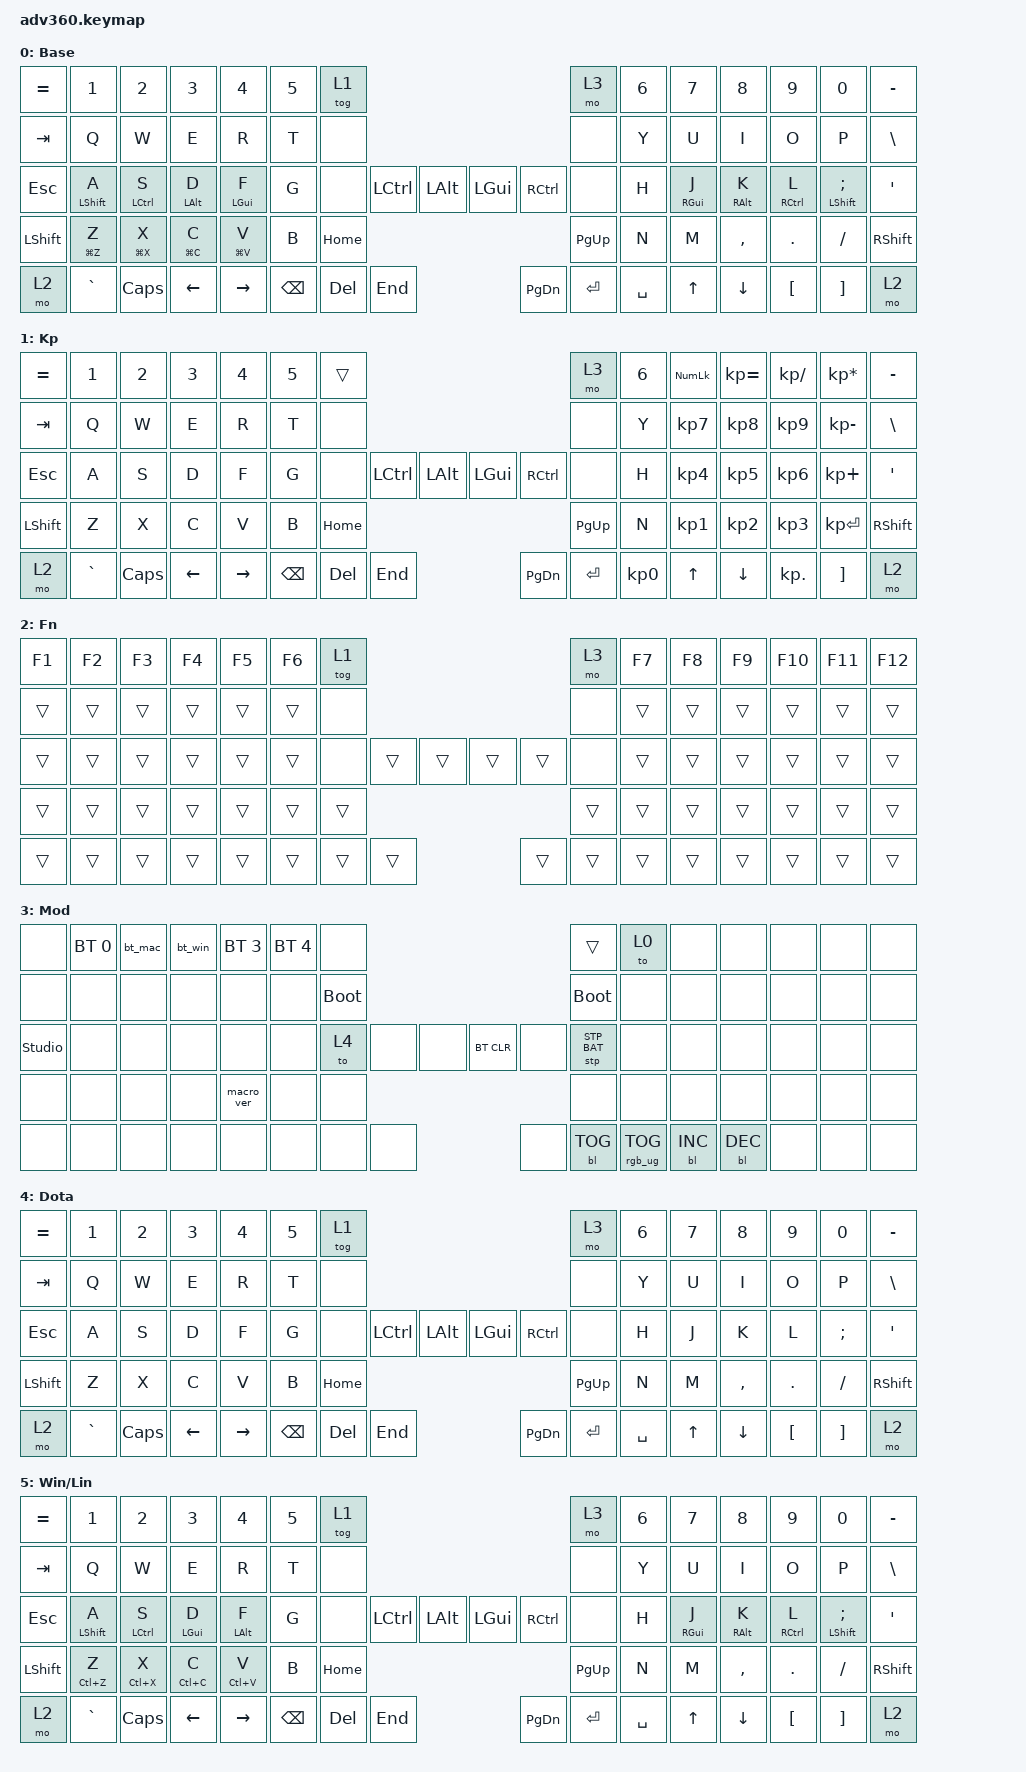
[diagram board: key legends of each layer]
#include <dt-bindings/zmk/stp.h>
#include <behaviors.dtsi>
#include <dt-bindings/zmk/backlight.h>
#include <dt-bindings/zmk/bt.h>
#include <dt-bindings/zmk/keys.h>
#include <dt-bindings/zmk/rgb.h>

/ {
    behaviors {
        #include "macros.dtsi"
        #include "version.dtsi"

        hm: homerow_mods {
            compatible = "zmk,behavior-hold-tap";
            label = "HOMEROW_MODS";
            #binding-cells = <2>;
            tapping-term-ms = <200>;
            quick_tap_ms = <175>;
            flavor = "tap-preferred";
            bindings = <&kp>, <&kp>;
            quick-tap-ms = <175>;
        };

        left_home_row_mod: left_home_row_mod {
            compatible = "zmk,behavior-hold-tap";
            label = "LEFT_HOME_ROW_MOD";
            bindings = <&kp>, <&kp>;
            #binding-cells = <2>;
            flavor = "balanced";
            tapping-term-ms = <280>;
            quick-tap-ms = <175>;
            require-prior-idle-ms = <150>;
            hold-trigger-key-positions = <0 1 2 3 4 5 6 14 15 16 17 18 19 20 28 29 30 31 32 33 34 35 36 46 47 48 49 50 51 52 60 61 62 63 64 65 66 67>;
            hold-trigger-on-release;
        };

        right_home_row_mod: right_home_row_mod {
            compatible = "zmk,behavior-hold-tap";
            label = "RIGHT_HOME_ROW_MOD";
            bindings = <&kp>, <&kp>;
            #binding-cells = <2>;
            tapping-term-ms = <280>;
            quick-tap-ms = <175>;
            require-prior-idle-ms = <150>;
            flavor = "balanced";
            hold-trigger-key-positions = <7 8 9 10 11 12 13 21 22 23 24 25 26 27 37 38 39 40 41 42 43 44 45 53 54 55 56 57 58 59 68 69 70 71 72 73 74 75>;
            hold-trigger-on-release;
        };
    };

    macros {
        bt_mac: bt_mac {
            compatible = "zmk,behavior-macro";
            #binding-cells = <0>;
            bindings = <&bt BT_SEL 1>, <&to 0>;
            display-name = "BT Mac";
        };

        bt_win: bt_win {
            compatible = "zmk,behavior-macro";
            #binding-cells = <0>;
            bindings = <&bt BT_SEL 2>, <&to 5>;
            display-name = "BT Win/Lin";
        };
    };

    keymap {
        compatible = "zmk,keymap";

        default_layer {
            display-name = "Base";
            bindings = 
&kp EQUAL  &kp N1                           &kp N2                             &kp N3                         &kp N4                         &kp N5  &tog 1                                                   &mo 3      &kp N6  &kp N7                          &kp N8                           &kp N9                               &kp N0                                    &kp MINUS
&kp TAB    &kp Q                            &kp W                              &kp E                          &kp R                          &kp T   &none                                                    &none      &kp Y   &kp U                           &kp I                            &kp O                                &kp P                                     &kp BSLH
&kp ESC    &left_home_row_mod LEFT_SHIFT A  &left_home_row_mod LEFT_CONTROL S  &left_home_row_mod LEFT_ALT D  &left_home_row_mod LEFT_GUI F  &kp G   &none     &kp LCTRL  &kp LALT      &kp LGUI   &kp RCTRL  &none      &kp H   &right_home_row_mod RIGHT_GUI J  &right_home_row_mod RIGHT_ALT K  &right_home_row_mod RIGHT_CONTROL L  &right_home_row_mod LEFT_SHIFT SEMICOLON  &kp SQT
&kp LSHFT  &left_home_row_mod LG(Z) Z       &left_home_row_mod LG(X) X         &left_home_row_mod LG(C) C     &left_home_row_mod LG(V) V     &kp B                        &kp HOME      &kp PG_UP                        &kp N   &kp M                           &kp COMMA                        &kp DOT                              &kp FSLH                                  &kp RSHFT
&mo 2      &kp GRAVE                        &kp CAPS                           &kp LEFT                       &kp RIGHT                              &kp BSPC  &kp DEL    &kp END       &kp PG_DN  &kp ENTER  &kp SPACE          &kp UP                          &kp DOWN                         &kp LBKT                             &kp RBKT                                  &mo 2
            >;
        };

        keypad {
            display-name = "Kp";
            bindings = 
&kp EQUAL  &kp N1     &kp N2    &kp N3    &kp N4     &kp N5  &trans                                                   &mo 3      &kp N6  &kp KP_NUM  &kp KP_EQUAL  &kp KP_DIVIDE  &kp KP_MULTIPLY  &kp MINUS
&kp TAB    &kp Q      &kp W     &kp E     &kp R      &kp T   &none                                                    &none      &kp Y   &kp KP_N7   &kp KP_N8     &kp KP_N9      &kp KP_MINUS     &kp BSLH
&kp ESC    &kp A      &kp S     &kp D     &kp F      &kp G   &none     &kp LCTRL  &kp LALT      &kp LGUI   &kp RCTRL  &none      &kp H   &kp KP_N4   &kp KP_N5     &kp KP_N6      &kp KP_PLUS      &kp SQT
&kp LSHFT  &kp Z      &kp X     &kp C     &kp V      &kp B                        &kp HOME      &kp PG_UP                        &kp N   &kp KP_N1   &kp KP_N2     &kp KP_N3      &kp KP_ENTER     &kp RSHFT
&mo 2      &kp GRAVE  &kp CAPS  &kp LEFT  &kp RIGHT          &kp BSPC  &kp DEL    &kp END       &kp PG_DN  &kp ENTER  &kp KP_N0          &kp UP      &kp DOWN      &kp KP_DOT     &kp RBKT         &mo 2
            >;
        };

        fn {
            display-name = "Fn";
            bindings = 
&kp F1  &kp F2  &kp F3  &kp F4  &kp F5  &kp F6  &tog 1                                      &mo 3   &kp F7  &kp F8  &kp F9  &kp F10  &kp F11  &kp F12
&trans  &trans  &trans  &trans  &trans  &trans  &none                                       &none   &trans  &trans  &trans  &trans   &trans   &trans
&trans  &trans  &trans  &trans  &trans  &trans  &none   &trans  &trans      &trans  &trans  &none   &trans  &trans  &trans  &trans   &trans   &trans
&trans  &trans  &trans  &trans  &trans  &trans                  &trans      &trans                  &trans  &trans  &trans  &trans   &trans   &trans
&trans  &trans  &trans  &trans  &trans          &trans  &trans  &trans      &trans  &trans  &trans          &trans  &trans  &trans   &trans   &trans
            >;
        };

        mod {
            display-name = "Mod";
            bindings = 
&none           &bt BT_SEL 0  &bt_mac  &bt_win  &bt BT_SEL 3  &bt BT_SEL 4  &none                                                  &trans           &to 0  &none       &none       &none  &none  &none
&none           &none         &none    &none    &none         &none         &bootloader                                            &bootloader      &none  &none       &none       &none  &none  &none
&studio_unlock  &none         &none    &none    &none         &none         &to 4        &none  &none      &bt BT_CLR  &none       &stp STP_BAT     &none  &none       &none       &none  &none  &none
&none           &none         &none    &none    &macro_ver    &none                             &none      &none                                    &none  &none       &none       &none  &none  &none
&none           &none         &none    &none    &none                       &none        &none  &none      &none       &bl BL_TOG  &rgb_ug RGB_TOG         &bl BL_INC  &bl BL_DEC  &none  &none  &none
            >;
        };

        extra1 {
            display-name = "Dota";
            bindings = 
&kp EQUAL  &kp N1     &kp N2    &kp N3    &kp N4     &kp N5  &tog 1                                                   &mo 3      &kp N6  &kp N7  &kp N8     &kp N9    &kp N0    &kp MINUS
&kp TAB    &kp Q      &kp W     &kp E     &kp R      &kp T   &none                                                    &none      &kp Y   &kp U   &kp I      &kp O     &kp P     &kp BSLH
&kp ESC    &kp A      &kp S     &kp D     &kp F      &kp G   &none     &kp LCTRL  &kp LALT      &kp LGUI   &kp RCTRL  &none      &kp H   &kp J   &kp K      &kp L     &kp SEMI  &kp SQT
&kp LSHFT  &kp Z      &kp X     &kp C     &kp V      &kp B                        &kp HOME      &kp PG_UP                        &kp N   &kp M   &kp COMMA  &kp DOT   &kp FSLH  &kp RSHFT
&mo 2      &kp GRAVE  &kp CAPS  &kp LEFT  &kp RIGHT          &kp BSPC  &kp DEL    &kp END       &kp PG_DN  &kp ENTER  &kp SPACE          &kp UP  &kp DOWN   &kp LBKT  &kp RBKT  &mo 2
            >;
        };

        extra2 {
            display-name = "Win/Lin";
            bindings = 
&kp EQUAL  &kp N1                           &kp N2                             &kp N3                         &kp N4                        &kp N5  &tog 1                                                   &mo 3      &kp N6  &kp N7                          &kp N8                           &kp N9                               &kp N0                                    &kp MINUS
&kp TAB    &kp Q                            &kp W                              &kp E                          &kp R                         &kp T   &none                                                    &none      &kp Y   &kp U                           &kp I                            &kp O                                &kp P                                     &kp BSLH
&kp ESC    &left_home_row_mod LEFT_SHIFT A  &left_home_row_mod LEFT_CONTROL S  &left_home_row_mod LEFT_GUI D  &left_home_row_mod LEFT_ALT F &kp G   &none     &kp LCTRL  &kp LALT      &kp LGUI   &kp RCTRL  &none      &kp H   &right_home_row_mod RIGHT_GUI J  &right_home_row_mod RIGHT_ALT K  &right_home_row_mod RIGHT_CONTROL L  &right_home_row_mod LEFT_SHIFT SEMICOLON  &kp SQT
&kp LSHFT  &left_home_row_mod LC(Z) Z       &left_home_row_mod LC(X) X         &left_home_row_mod LC(C) C     &left_home_row_mod LC(V) V    &kp B                        &kp HOME      &kp PG_UP                        &kp N   &kp M                           &kp COMMA                        &kp DOT                              &kp FSLH                                  &kp RSHFT
&mo 2      &kp GRAVE                        &kp CAPS                           &kp LEFT                       &kp RIGHT                             &kp BSPC  &kp DEL    &kp END       &kp PG_DN  &kp ENTER  &kp SPACE          &kp UP                          &kp DOWN                         &kp LBKT                             &kp RBKT                                  &mo 2
            >;
        };

        extra3 {
            display-name = "Cyan";
            status = "reserved";
        };

        extra4 {
            display-name = "Yellow";
            status = "reserved";
        };
    };
};
